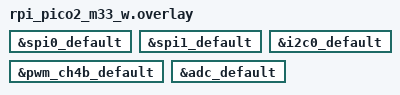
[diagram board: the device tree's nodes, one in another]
/*
 * Copyright (c) 2025 TiaC Systems
 * SPDX-License-Identifier: Apache-2.0
 */

#include "rpipico_r3.dtsi"

/* link to pinctrl node from board for rpi_pico2/rp2350a/m33/w */
spi0_pico: &spi0_default {};

/* link to pinctrl node from board extensions for rpi_pico2/rp2350a/m33/w */
spi1_pico: &spi1_default {};

/* link to pinctrl node from board for rpi_pico2/rp2350a/m33/w */
i2c0_pico: &i2c0_default {};

/* link to pinctrl node from board for rpi_pico2/rp2350a/m33/w */
pwm_pico: &pwm_ch4b_default {};

/* link to pinctrl node from board for rpi_pico2/rp2350a/m33/w */
adc_pico: &adc_default {};
